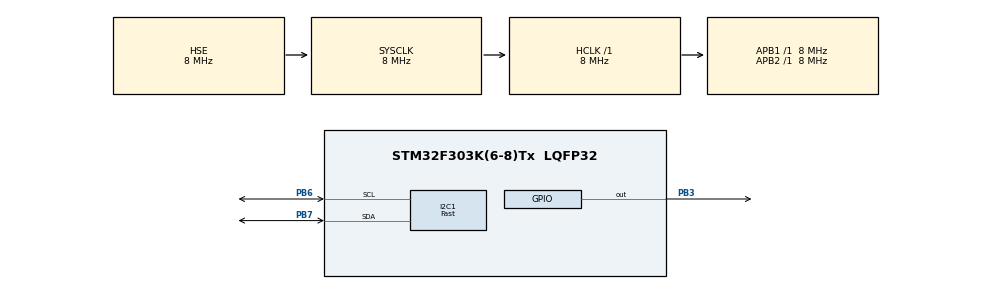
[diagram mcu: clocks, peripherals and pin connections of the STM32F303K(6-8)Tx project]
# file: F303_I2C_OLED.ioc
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I2C1.I2C_Speed_Mode=I2C_Fast
I2C1.Timing=0x0000020B
Mcu.Family=STM32F3
Mcu.Name=STM32F303K(6-8)Tx
Mcu.Package=LQFP32
NVIC.PriorityGroup=NVIC_PRIORITYGROUP_4
PA13.Mode=Serial_Wire
PA13.Signal=SYS_JTMS-SWDIO
PA14.Mode=Serial_Wire
PA14.Signal=SYS_JTCK-SWCLK
PB3.Signal=GPIO_Output
PB6.Mode=I2C
PB6.Signal=I2C1_SCL
PB7.Mode=I2C
PB7.Signal=I2C1_SDA
PF0\ /\ OSC_IN.Mode=HSE-External-Oscillator
PF0\ /\ OSC_IN.Signal=RCC_OSC_IN
PF1\ /\ OSC_OUT.Mode=HSE-External-Oscillator
PF1\ /\ OSC_OUT.Signal=RCC_OSC_OUT
ProjectManager.HeapSize=0x200
ProjectManager.StackSize=0x400
ProjectManager.TargetToolchain=STM32CubeIDE
RCC.AHBFreq_Value=8000000
RCC.APB1Freq_Value=8000000
RCC.APB1TimFreq_Value=8000000
RCC.APB2Freq_Value=8000000
RCC.APB2TimFreq_Value=8000000
RCC.CortexFreq_Value=8000000
RCC.HCLKFreq_Value=8000000
RCC.HSE_VALUE=8000000
RCC.HSI_VALUE=8000000
RCC.PLLMUL=RCC_PLL_MUL6
RCC.SYSCLKFreq_VALUE=8000000
RCC.SYSCLKSourceVirtual=RCC_SYSCLKSOURCE_HSE
board=custom

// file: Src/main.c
/* USER CODE BEGIN Header */
/**
  ******************************************************************************
  * @file           : main.c
  * @brief          : Main program body
  ******************************************************************************
  * @attention
  *
  * <h2><center>&copy; Copyright (c) 2019 STMicroelectronics.
  * All rights reserved.</center></h2>
  *
  * This software component is licensed by ST under BSD 3-Clause license,
  * the "License"; You may not use this file except in compliance with the
  * License. You may obtain a copy of the License at:
  *                        opensource.org/licenses/BSD-3-Clause
  *
  ******************************************************************************
  */
/* USER CODE END Header */

#include <ssd1306_basic.h>
#include "main.h"

I2C_HandleTypeDef hi2c1;

void SystemClock_Config(void);
static void MX_GPIO_Init(void);
static void MX_I2C1_Init(void);

int main(void)
{

  /* MCU Configuration--------------------------------------------------------*/

  /* Reset of all peripherals, Initializes the Flash interface and the Systick. */
  HAL_Init();

  /* Configure the system clock */
  SystemClock_Config();

  /* Initialize all configured peripherals */
  MX_GPIO_Init();
  MX_I2C1_Init();
  /* USER CODE BEGIN 2 */

  ssd1306_t* ssd1306_1 = ssd1306_new(&hi2c1, 0x78); // 0x79

double data = -3.0076;
int data_i = -12003;
uint8_t decimales = 4;

SSD1306_Putdouble(ssd1306_1, data, decimales, 1);
SSD1306_Putdouble(ssd1306_1, data, decimales, 2);
SSD1306_Putint(ssd1306_1, data_i, 3);
SSD1306_Putdouble(ssd1306_1, data, decimales, 4);
SSD1306_Putdouble(ssd1306_1, data, decimales, 5);
SSD1306_UpdateScreen(ssd1306_1);
  /* USER CODE END 2 */

  /* Infinite loop */
  while (1)
  {

  }
}

void SystemClock_Config(void)
{
  RCC_OscInitTypeDef RCC_OscInitStruct = {0};
  RCC_ClkInitTypeDef RCC_ClkInitStruct = {0};
  RCC_PeriphCLKInitTypeDef PeriphClkInit = {0};

  /** Initializes the CPU, AHB and APB busses clocks
  */
  RCC_OscInitStruct.OscillatorType = RCC_OSCILLATORTYPE_HSI|RCC_OSCILLATORTYPE_HSE;
  RCC_OscInitStruct.HSEState = RCC_HSE_ON;
  RCC_OscInitStruct.HSIState = RCC_HSI_ON;
  RCC_OscInitStruct.HSICalibrationValue = RCC_HSICALIBRATION_DEFAULT;
  RCC_OscInitStruct.PLL.PLLState = RCC_PLL_NONE;
  if (HAL_RCC_OscConfig(&RCC_OscInitStruct) != HAL_OK)
  {
    Error_Handler();
  }
  /** Initializes the CPU, AHB and APB busses clocks
  */
  RCC_ClkInitStruct.ClockType = RCC_CLOCKTYPE_HCLK|RCC_CLOCKTYPE_SYSCLK
                              |RCC_CLOCKTYPE_PCLK1|RCC_CLOCKTYPE_PCLK2;
  RCC_ClkInitStruct.SYSCLKSource = RCC_SYSCLKSOURCE_HSE;
  RCC_ClkInitStruct.AHBCLKDivider = RCC_SYSCLK_DIV1;
  RCC_ClkInitStruct.APB1CLKDivider = RCC_HCLK_DIV1;
  RCC_ClkInitStruct.APB2CLKDivider = RCC_HCLK_DIV1;

  if (HAL_RCC_ClockConfig(&RCC_ClkInitStruct, FLASH_LATENCY_0) != HAL_OK)
  {
    Error_Handler();
  }
  PeriphClkInit.PeriphClockSelection = RCC_PERIPHCLK_I2C1;
  PeriphClkInit.I2c1ClockSelection = RCC_I2C1CLKSOURCE_HSI;
  if (HAL_RCCEx_PeriphCLKConfig(&PeriphClkInit) != HAL_OK)
  {
    Error_Handler();
  }
}

static void MX_I2C1_Init(void)
{

  hi2c1.Instance = I2C1;
  hi2c1.Init.Timing = 0x0000020B;
  hi2c1.Init.OwnAddress1 = 0;
  hi2c1.Init.AddressingMode = I2C_ADDRESSINGMODE_7BIT;
  hi2c1.Init.DualAddressMode = I2C_DUALADDRESS_DISABLE;
  hi2c1.Init.OwnAddress2 = 0;
  hi2c1.Init.OwnAddress2Masks = I2C_OA2_NOMASK;
  hi2c1.Init.GeneralCallMode = I2C_GENERALCALL_DISABLE;
  hi2c1.Init.NoStretchMode = I2C_NOSTRETCH_DISABLE;
  if (HAL_I2C_Init(&hi2c1) != HAL_OK)
  {
    Error_Handler();
  }
  /** Configure Analogue filter
  */
  if (HAL_I2CEx_ConfigAnalogFilter(&hi2c1, I2C_ANALOGFILTER_ENABLE) != HAL_OK)
  {
    Error_Handler();
  }
  /** Configure Digital filter
  */
  if (HAL_I2CEx_ConfigDigitalFilter(&hi2c1, 0) != HAL_OK)
  {
    Error_Handler();
  }

}

static void MX_GPIO_Init(void)
{
  GPIO_InitTypeDef GPIO_InitStruct = {0};

  /* GPIO Ports Clock Enable */
  __HAL_RCC_GPIOF_CLK_ENABLE();
  __HAL_RCC_GPIOA_CLK_ENABLE();
  __HAL_RCC_GPIOB_CLK_ENABLE();

  /*Configure GPIO pin Output Level */
  HAL_GPIO_WritePin(GPIOB, GPIO_PIN_3, GPIO_PIN_RESET);

  /*Configure GPIO pin : PB3 */
  GPIO_InitStruct.Pin = GPIO_PIN_3;
  GPIO_InitStruct.Mode = GPIO_MODE_OUTPUT_PP;
  GPIO_InitStruct.Pull = GPIO_NOPULL;
  GPIO_InitStruct.Speed = GPIO_SPEED_FREQ_LOW;
  HAL_GPIO_Init(GPIOB, &GPIO_InitStruct);

}

void Error_Handler(void)
{
}

/************************ (C) COPYRIGHT STMicroelectronics *****END OF FILE****/
